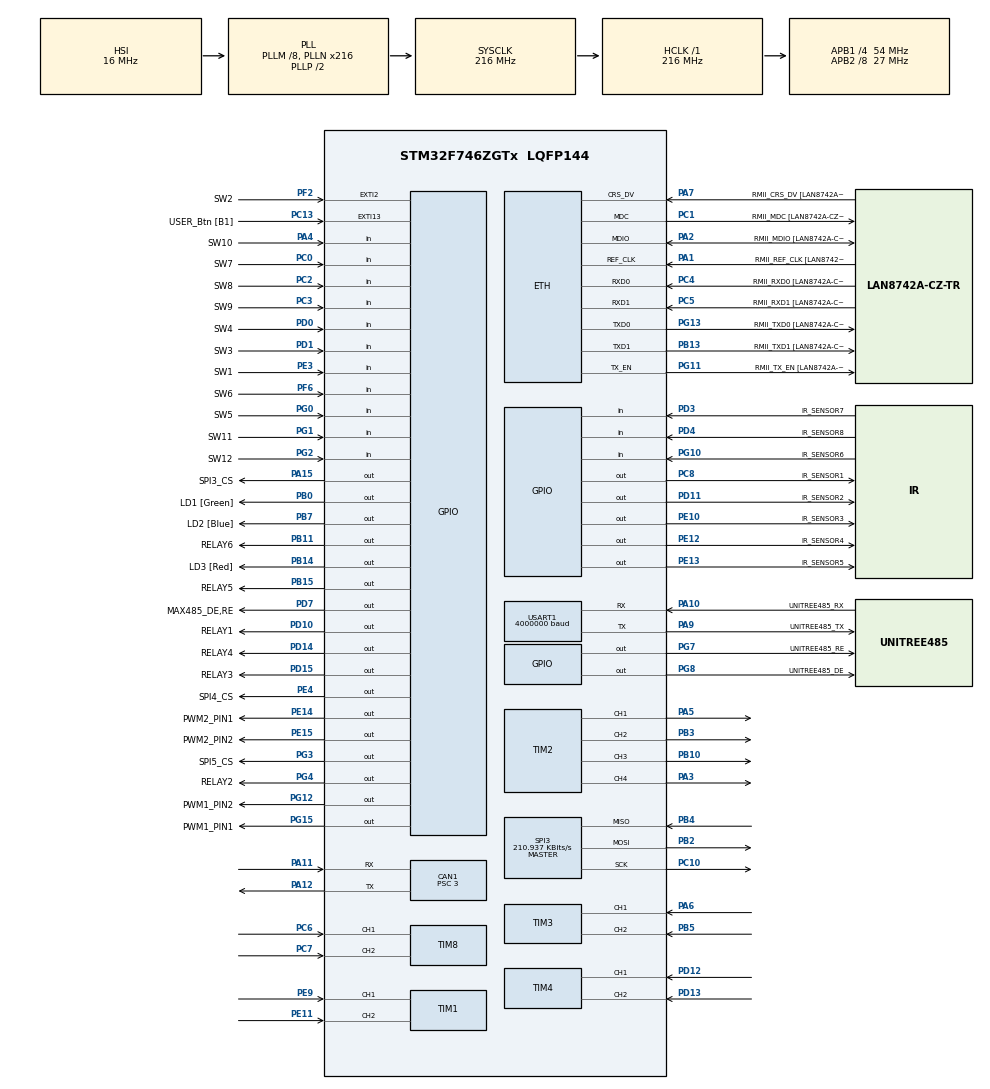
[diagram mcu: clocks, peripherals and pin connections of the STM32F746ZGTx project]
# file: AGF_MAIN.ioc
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CAN1.ABOM=ENABLE
CAN1.BS1=CAN_BS1_16TQ
CAN1.CalculateBaudRate=1000000
CAN1.CalculateTimeBit=1000
CAN1.CalculateTimeQuantum=55.55555555555556
CAN1.NART=ENABLE
CAN1.Prescaler=3
ETH.MediaInterface=HAL_ETH_RMII_MODE
ETH.PHY_Name=LAN8742A_PHY_ADDRESS
ETH.PHY_Value=0
ETH.PhyAddress=0
FREERTOS.Tasks01=Emergency,30,256,EmergencyTask,Default,NULL,Dynamic,NULL,NULL;JoyStick_Task,8,256,Joy_Task,Default,NULL,Dynamic,NULL,NULL;Motion_Control_,8,256,Motion_Control,Default,NULL,Dynamic,NULL,NULL
FREERTOS.configUSE_NEWLIB_REENTRANT=1
Mcu.Family=STM32F7
Mcu.Name=STM32F746ZGTx
Mcu.Package=LQFP144
NVIC.CAN1_RX0_IRQn=true\:5\:0\:false\:false\:true\:true\:true\:true\:true
NVIC.CAN1_RX1_IRQn=true\:5\:0\:false\:false\:true\:true\:true\:true\:true
NVIC.PriorityGroup=NVIC_PRIORITYGROUP_4
NVIC.TIM7_IRQn=true\:15\:0\:false\:false\:true\:false\:false\:true\:true
NVIC.TimeBase=TIM7_IRQn
NVIC.TimeBaseIP=TIM7
PA1.GPIO_Label=RMII_REF_CLK [LAN8742A-CZ-TR_REFCLK0]
PA1.Mode=RMII
PA1.Signal=ETH_REF_CLK
PA10.GPIO_Label=UNITREE485_RX
PA10.Mode=Asynchronous
PA10.Signal=USART1_RX
PA11.Mode=CAN_Activate
PA11.Signal=CAN1_RX
PA12.Mode=CAN_Activate
PA12.Signal=CAN1_TX
PA13.GPIO_Label=TMS
PA13.Mode=Serial_Wire
PA13.Signal=SYS_JTMS-SWDIO
PA14.GPIO_Label=TCK
PA14.Mode=Serial_Wire
PA14.Signal=SYS_JTCK-SWCLK
PA15.GPIO_Label=SPI3_CS
PA15.GPIO_Speed=GPIO_SPEED_FREQ_LOW
PA15.Signal=GPIO_Output
PA2.GPIO_Label=RMII_MDIO [LAN8742A-CZ-TR_MDIO]
PA2.Mode=RMII
PA2.Signal=ETH_MDIO
PA3.Signal=S_TIM2_CH4
PA4.GPIO_Label=SW10
PA4.Signal=GPIO_Input
PA5.Signal=S_TIM2_CH1_ETR
PA6.Signal=S_TIM3_CH1
PA7.GPIO_Label=RMII_CRS_DV [LAN8742A-CZ-TR_CRS_DV]
PA7.Mode=RMII
PA7.Signal=ETH_CRS_DV
PA9.GPIO_Label=UNITREE485_TX
PA9.Mode=Asynchronous
PA9.Signal=USART1_TX
PB0.GPIO_Label=LD1 [Green]
PB0.Signal=GPIO_Output
PB10.Signal=S_TIM2_CH3
PB11.GPIO_Label=RELAY6
PB11.Signal=GPIO_Output
PB13.GPIO_Label=RMII_TXD1 [LAN8742A-CZ-TR_TXD1]
PB13.Mode=RMII
PB13.Signal=ETH_TXD1
PB14.GPIO_Label=LD3 [Red]
PB14.Signal=GPIO_Output
PB15.GPIO_Label=RELAY5
PB15.Signal=GPIO_Output
PB2.Mode=Full_Duplex_Master
PB2.Signal=SPI3_MOSI
PB3.Signal=S_TIM2_CH2
PB4.Mode=Full_Duplex_Master
PB4.Signal=SPI3_MISO
PB5.Signal=S_TIM3_CH2
PB7.GPIO_Label=LD2 [Blue]
PB7.Signal=GPIO_Output
PB8.Signal=I2C1_SCL
PB9.Signal=I2C1_SDA
PC0.GPIO_Label=SW7
PC0.Signal=GPIO_Input
PC1.GPIO_Label=RMII_MDC [LAN8742A-CZ-TR_MDC]
PC1.Mode=RMII
PC1.Signal=ETH_MDC
PC10.Mode=Full_Duplex_Master
PC10.Signal=SPI3_SCK
PC13.GPIO_Label=USER_Btn [B1]
PC13.Signal=GPXTI13
PC14/OSC32_IN.Mode=LSE-External-Oscillator
PC14/OSC32_IN.Signal=RCC_OSC32_IN
PC15/OSC32_OUT.Mode=LSE-External-Oscillator
PC15/OSC32_OUT.Signal=RCC_OSC32_OUT
PC2.GPIO_Label=SW8
PC2.Signal=GPIO_Input
PC3.GPIO_Label=SW9
PC3.Signal=GPIO_Input
PC4.GPIO_Label=RMII_RXD0 [LAN8742A-CZ-TR_RXD0]
PC4.Mode=RMII
PC4.Signal=ETH_RXD0
PC5.GPIO_Label=RMII_RXD1 [LAN8742A-CZ-TR_RXD1]
PC5.Mode=RMII
PC5.Signal=ETH_RXD1
PC6.Signal=S_TIM8_CH1
PC7.Signal=S_TIM8_CH2
PC8.GPIO_Label=IR_SENSOR1
PC8.Signal=GPIO_Output
PD0.GPIO_Label=SW4
PD0.Signal=GPIO_Input
PD1.GPIO_Label=SW3
PD1.Signal=GPIO_Input
PD10.GPIO_Label=RELAY1
PD10.Signal=GPIO_Output
PD11.GPIO_Label=IR_SENSOR2
PD11.Signal=GPIO_Output
PD12.Signal=S_TIM4_CH1
PD13.Signal=S_TIM4_CH2
PD14.GPIO_Label=RELAY4
PD14.Signal=GPIO_Output
PD15.GPIO_Label=RELAY3
PD15.Signal=GPIO_Output
PD2.Signal=UART5_RX
PD3.GPIO_Label=IR_SENSOR7
PD3.Signal=GPIO_Input
PD4.GPIO_Label=IR_SENSOR8
PD4.Signal=GPIO_Input
PD6.GPIO_Label=MAX485_RO_RX
PD6.Signal=USART2_RX
PD7.GPIO_Label=MAX485_DE,RE
PD7.Signal=GPIO_Output
PD8.GPIO_Label=STLK_RX [STM32F103CBT6_PA3]
PD8.GPIO_PuPd=GPIO_PULLUP
PD8.Signal=USART3_TX
PD9.GPIO_Label=STLK_TX [STM32F103CBT6_PA2]
PD9.GPIO_PuPd=GPIO_PULLUP
PD9.Signal=USART3_RX
PE10.GPIO_Label=IR_SENSOR3
PE10.Signal=GPIO_Output
PE11.Signal=S_TIM1_CH2
PE12.GPIO_Label=IR_SENSOR4
PE12.Signal=GPIO_Output
PE13.GPIO_Label=IR_SENSOR5
PE13.Signal=GPIO_Output
PE14.GPIO_Label=PWM2_PIN1
PE14.Signal=GPIO_Output
PE15.GPIO_Label=PWM2_PIN2
PE15.Signal=GPIO_Output
PE3.GPIO_Label=SW1
PE3.Signal=GPIO_Input
PE4.GPIO_Label=SPI4_CS
PE4.Signal=GPIO_Output
PE7.Signal=UART7_RX
PE9.Signal=S_TIM1_CH1
PF2.GPIO_Label=SW2
PF2.GPIO_ModeDefaultEXTI=GPIO_MODE_IT_FALLING
PF2.Signal=GPXTI2
PF6.GPIO_Label=SW6
PF6.Signal=GPIO_Input
PG0.GPIO_Label=SW5
PG0.Signal=GPIO_Input
PG1.GPIO_Label=SW11
PG1.Signal=GPIO_Input
PG10.GPIO_Label=IR_SENSOR6
PG10.Signal=GPIO_Input
PG11.GPIO_Label=RMII_TX_EN [LAN8742A-CZ-TR_TXEN]
PG11.Mode=RMII
PG11.Signal=ETH_TX_EN
PG12.GPIO_Label=PWM1_PIN2
PG12.Signal=GPIO_Output
PG13.GPIO_Label=RMII_TXD0 [LAN8742A-CZ-TR_TXD0]
PG13.Mode=RMII
PG13.Signal=ETH_TXD0
PG15.GPIO_Label=PWM1_PIN1
PG15.Signal=GPIO_Output
PG2.GPIO_Label=SW12
PG2.Signal=GPIO_Input
PG3.GPIO_Label=SPI5_CS
PG3.Signal=GPIO_Output
PG4.GPIO_Label=RELAY2
PG4.Signal=GPIO_Output
PG7.GPIO_Label=UNITREE485_RE
PG7.Signal=GPIO_Output
PG8.GPIO_Label=UNITREE485_DE
PG8.Signal=GPIO_Output
PH0/OSC_IN.GPIO_Label=MCO [STM32F103CBT6_PA8]
PH0/OSC_IN.Mode=HSE-External-Oscillator
PH0/OSC_IN.Signal=RCC_OSC_IN
PH1/OSC_OUT.Mode=HSE-External-Oscillator
PH1/OSC_OUT.Signal=RCC_OSC_OUT
ProjectManager.HeapSize=0x200
ProjectManager.StackSize=0x400
ProjectManager.TargetToolchain=STM32CubeIDE
RCC.48MHZClocksFreq_Value=24000000
RCC.AHBFreq_Value=216000000
RCC.APB1CLKDivider=RCC_HCLK_DIV4
RCC.APB1Freq_Value=54000000
RCC.APB1TimFreq_Value=108000000
RCC.APB2CLKDivider=RCC_HCLK_DIV8
RCC.APB2Freq_Value=27000000
RCC.APB2TimFreq_Value=54000000
RCC.CortexFreq_Value=216000000
RCC.HCLKFreq_Value=216000000
RCC.HSE_VALUE=25000000
RCC.HSI_VALUE=16000000
RCC.PLLM=8
RCC.PLLMUL=RCC_PLL_MUL9
RCC.PLLN=216
RCC.PLLQ=3
RCC.PRESCALERUSB=RCC_USBCLKSOURCE_PLL_DIV1_5
RCC.SYSCLKFreq_VALUE=216000000
RCC.SYSCLKSource=RCC_SYSCLKSOURCE_PLLCLK
RCC.SYSCLKSourceVirtual=RCC_SYSCLKSOURCE_PLLCLK
RCC.USART1CLockSelection=RCC_USART1CLKSOURCE_SYSCLK
RCC.USBFreq_Value=144000000
RCC.VCOOutputFreq_Value=432000000
SH.S_TIM1_CH1.0=TIM1_CH1,Encoder_Interface
SH.S_TIM1_CH2.0=TIM1_CH2,Encoder_Interface
SH.S_TIM2_CH1_ETR.0=TIM2_CH1,PWM Generation1 CH1
SH.S_TIM2_CH2.0=TIM2_CH2,PWM Generation2 CH2
SH.S_TIM2_CH3.0=TIM2_CH3,PWM Generation3 CH3
SH.S_TIM2_CH4.0=TIM2_CH4,PWM Generation4 CH4
SH.S_TIM3_CH1.0=TIM3_CH1,Encoder_Interface
SH.S_TIM3_CH2.0=TIM3_CH2,Encoder_Interface
SH.S_TIM4_CH1.0=TIM4_CH1,Encoder_Interface
SH.S_TIM4_CH2.0=TIM4_CH2,Encoder_Interface
SH.S_TIM8_CH1.0=TIM8_CH1,Encoder_Interface
SH.S_TIM8_CH2.0=TIM8_CH2,Encoder_Interface
SPI3.BaudRatePrescaler=SPI_BAUDRATEPRESCALER_256
SPI3.CLKPhase=SPI_PHASE_1EDGE
SPI3.CLKPolarity=SPI_POLARITY_HIGH
SPI3.CalculateBaudRate=210.937 KBits/s
SPI3.DataSize=SPI_DATASIZE_8BIT
SPI3.Direction=SPI_DIRECTION_2LINES
SPI3.FirstBit=SPI_FIRSTBIT_LSB
SPI3.Mode=SPI_MODE_MASTER
SPI3.VirtualType=VM_MASTER
TIM2.Channel-PWM\ Generation1\ CH1=TIM_CHANNEL_1
TIM2.Channel-PWM\ Generation2\ CH2=TIM_CHANNEL_2
TIM2.Channel-PWM\ Generation3\ CH3=TIM_CHANNEL_3
TIM2.Channel-PWM\ Generation4\ CH4=TIM_CHANNEL_4
TIM3.EncoderMode=TIM_ENCODERMODE_TI12
TIM4.EncoderMode=TIM_ENCODERMODE_TI12
TIM8.CounterMode=TIM_COUNTERMODE_DOWN
TIM8.IC1Polarity=TIM_ICPOLARITY_RISING
USART1.BaudRate=4000000
USART1.VirtualMode-Asynchronous=VM_ASYNC
VP_FREERTOS_VS_CMSIS_V2.Mode=CMSIS_V2
VP_SYS_VS_tim7.Mode=TIM7
board=NUCLEO-F746ZG

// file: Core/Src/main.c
/* USER CODE BEGIN Header */
/**
  ******************************************************************************
  * @file           : main.c
  * @brief          : Main program body
  ******************************************************************************
  * @attention
  *
  * Copyright (c) 2026 STMicroelectronics.
  * All rights reserved.
  *
  * This software is licensed under terms that can be found in the LICENSE file
  * in the root directory of this software component.
  * If no LICENSE file comes with this software, it is provided AS-IS.
  *
  ******************************************************************************
  */
/* USER CODE END Header */
#include "main.h"
#include "string.h"
#include "cmsis_os.h"

/* USER CODE BEGIN Includes */
#include "WEncoder_CAN.h"
#include "motor_control.h"
#include "robstride.h"
/* USER CODE END Includes */

#if defined ( __ICCARM__ ) /*!< IAR Compiler */
#pragma location=0x2004c000
ETH_DMADescTypeDef  DMARxDscrTab[ETH_RX_DESC_CNT]; /* Ethernet Rx DMA Descriptors */
#pragma location=0x2004c0a0
ETH_DMADescTypeDef  DMATxDscrTab[ETH_TX_DESC_CNT]; /* Ethernet Tx DMA Descriptors */

#elif defined ( __CC_ARM )  /* MDK ARM Compiler */

__attribute__((at(0x2004c000))) ETH_DMADescTypeDef  DMARxDscrTab[ETH_RX_DESC_CNT]; /* Ethernet Rx DMA Descriptors */
__attribute__((at(0x2004c0a0))) ETH_DMADescTypeDef  DMATxDscrTab[ETH_TX_DESC_CNT]; /* Ethernet Tx DMA Descriptors */

#elif defined ( __GNUC__ ) /* GNU Compiler */

ETH_DMADescTypeDef DMARxDscrTab[ETH_RX_DESC_CNT] __attribute__((section(".RxDecripSection"))); /* Ethernet Rx DMA Descriptors */
ETH_DMADescTypeDef DMATxDscrTab[ETH_TX_DESC_CNT] __attribute__((section(".TxDecripSection")));   /* Ethernet Tx DMA Descriptors */
#endif

ETH_TxPacketConfig TxConfig;

CAN_HandleTypeDef hcan1;

ETH_HandleTypeDef heth;

SPI_HandleTypeDef hspi3;

TIM_HandleTypeDef htim1;
TIM_HandleTypeDef htim2;
TIM_HandleTypeDef htim3;
TIM_HandleTypeDef htim4;
TIM_HandleTypeDef htim8;

UART_HandleTypeDef huart1;

/* Definitions for Emergency */
osThreadId_t EmergencyHandle;
const osThreadAttr_t Emergency_attributes = {
  .name = "Emergency",
  .stack_size = 256 * 4,
  .priority = (osPriority_t) osPriorityNormal6,
};
/* Definitions for JoyStick_Task */
osThreadId_t JoyStick_TaskHandle;
const osThreadAttr_t JoyStick_Task_attributes = {
  .name = "JoyStick_Task",
  .stack_size = 256 * 4,
  .priority = (osPriority_t) osPriorityLow,
};
/* Definitions for Motion_Control_ */
osThreadId_t Motion_Control_Handle;
const osThreadAttr_t Motion_Control__attributes = {
  .name = "Motion_Control_",
  .stack_size = 256 * 4,
  .priority = (osPriority_t) osPriorityLow,
};

void SystemClock_Config(void);
static void MX_GPIO_Init(void);
static void MX_ETH_Init(void);
static void MX_CAN1_Init(void);
static void MX_SPI3_Init(void);
static void MX_TIM1_Init(void);
static void MX_TIM2_Init(void);
static void MX_TIM3_Init(void);
static void MX_TIM4_Init(void);
static void MX_TIM8_Init(void);
static void MX_USART1_UART_Init(void);
void EmergencyTask(void *argument);
void Joy_Task(void *argument);
void Motion_Control(void *argument);

int main(void)
{

  /* MCU Configuration--------------------------------------------------------*/

  /* Reset of all peripherals, Initializes the Flash interface and the Systick. */
  HAL_Init();

  /* Configure the system clock */
  SystemClock_Config();

  /* Initialize all configured peripherals */
  MX_GPIO_Init();
  MX_ETH_Init();
  MX_CAN1_Init();
  MX_SPI3_Init();
  MX_TIM1_Init();
  MX_TIM2_Init();
  MX_TIM3_Init();
  MX_TIM4_Init();
  MX_TIM8_Init();
  MX_USART1_UART_Init();

  /* Init scheduler */
  osKernelInitialize();

  /* Create the thread(s) */
  /* creation of Emergency */
  EmergencyHandle = osThreadNew(EmergencyTask, NULL, &Emergency_attributes);

  /* creation of JoyStick_Task */
  JoyStick_TaskHandle = osThreadNew(Joy_Task, NULL, &JoyStick_Task_attributes);

  /* creation of Motion_Control_ */
  Motion_Control_Handle = osThreadNew(Motion_Control, NULL, &Motion_Control__attributes);

  /* Start scheduler */
  osKernelStart();

  /* We should never get here as control is now taken by the scheduler */

  /* Infinite loop */
  while (1)
  {

  }
}

void SystemClock_Config(void)
{
  RCC_OscInitTypeDef RCC_OscInitStruct = {0};
  RCC_ClkInitTypeDef RCC_ClkInitStruct = {0};

  /** Configure LSE Drive Capability
  */
  HAL_PWR_EnableBkUpAccess();

  /** Configure the main internal regulator output voltage
  */
  __HAL_RCC_PWR_CLK_ENABLE();
  __HAL_PWR_VOLTAGESCALING_CONFIG(PWR_REGULATOR_VOLTAGE_SCALE1);

  /** Initializes the RCC Oscillators according to the specified parameters
  * in the RCC_OscInitTypeDef structure.
  */
  RCC_OscInitStruct.OscillatorType = RCC_OSCILLATORTYPE_HSI;
  RCC_OscInitStruct.HSIState = RCC_HSI_ON;
  RCC_OscInitStruct.HSICalibrationValue = RCC_HSICALIBRATION_DEFAULT;
  RCC_OscInitStruct.PLL.PLLState = RCC_PLL_ON;
  RCC_OscInitStruct.PLL.PLLSource = RCC_PLLSOURCE_HSI;
  RCC_OscInitStruct.PLL.PLLM = 8;
  RCC_OscInitStruct.PLL.PLLN = 216;
  RCC_OscInitStruct.PLL.PLLP = RCC_PLLP_DIV2;
  RCC_OscInitStruct.PLL.PLLQ = 3;
  if (HAL_RCC_OscConfig(&RCC_OscInitStruct) != HAL_OK)
  {
    Error_Handler();
  }

  /** Activate the Over-Drive mode
  */
  if (HAL_PWREx_EnableOverDrive() != HAL_OK)
  {
    Error_Handler();
  }

  /** Initializes the CPU, AHB and APB buses clocks
  */
  RCC_ClkInitStruct.ClockType = RCC_CLOCKTYPE_HCLK|RCC_CLOCKTYPE_SYSCLK
                              |RCC_CLOCKTYPE_PCLK1|RCC_CLOCKTYPE_PCLK2;
  RCC_ClkInitStruct.SYSCLKSource = RCC_SYSCLKSOURCE_PLLCLK;
  RCC_ClkInitStruct.AHBCLKDivider = RCC_SYSCLK_DIV1;
  RCC_ClkInitStruct.APB1CLKDivider = RCC_HCLK_DIV4;
  RCC_ClkInitStruct.APB2CLKDivider = RCC_HCLK_DIV8;

  if (HAL_RCC_ClockConfig(&RCC_ClkInitStruct, FLASH_LATENCY_7) != HAL_OK)
  {
    Error_Handler();
  }
}

static void MX_CAN1_Init(void)
{

  hcan1.Instance = CAN1;
  hcan1.Init.Prescaler = 3;
  hcan1.Init.Mode = CAN_MODE_NORMAL;
  hcan1.Init.SyncJumpWidth = CAN_SJW_1TQ;
  hcan1.Init.TimeSeg1 = CAN_BS1_16TQ;
  hcan1.Init.TimeSeg2 = CAN_BS2_1TQ;
  hcan1.Init.TimeTriggeredMode = DISABLE;
  hcan1.Init.AutoBusOff = ENABLE;
  hcan1.Init.AutoWakeUp = DISABLE;
  hcan1.Init.AutoRetransmission = ENABLE;
  hcan1.Init.ReceiveFifoLocked = DISABLE;
  hcan1.Init.TransmitFifoPriority = DISABLE;
  if (HAL_CAN_Init(&hcan1) != HAL_OK)
  {
    Error_Handler();
  }

}

static void MX_ETH_Init(void)
{

   static uint8_t MACAddr[6];

  heth.Instance = ETH;
  MACAddr[0] = 0x00;
  MACAddr[1] = 0x80;
  MACAddr[2] = 0xE1;
  MACAddr[3] = 0x00;
  MACAddr[4] = 0x00;
  MACAddr[5] = 0x00;
  heth.Init.MACAddr = &MACAddr[0];
  heth.Init.MediaInterface = HAL_ETH_RMII_MODE;
  heth.Init.TxDesc = DMATxDscrTab;
  heth.Init.RxDesc = DMARxDscrTab;
  heth.Init.RxBuffLen = 1524;

  if (HAL_ETH_Init(&heth) != HAL_OK)
  {
    Error_Handler();
  }

  memset(&TxConfig, 0 , sizeof(ETH_TxPacketConfig));
  TxConfig.Attributes = ETH_TX_PACKETS_FEATURES_CSUM | ETH_TX_PACKETS_FEATURES_CRCPAD;
  TxConfig.ChecksumCtrl = ETH_CHECKSUM_IPHDR_PAYLOAD_INSERT_PHDR_CALC;
  TxConfig.CRCPadCtrl = ETH_CRC_PAD_INSERT;

}

static void MX_SPI3_Init(void)
{

  /* SPI3 parameter configuration*/
  hspi3.Instance = SPI3;
  hspi3.Init.Mode = SPI_MODE_MASTER;
  hspi3.Init.Direction = SPI_DIRECTION_2LINES;
  hspi3.Init.DataSize = SPI_DATASIZE_8BIT;
  hspi3.Init.CLKPolarity = SPI_POLARITY_HIGH;
  hspi3.Init.CLKPhase = SPI_PHASE_1EDGE;
  hspi3.Init.NSS = SPI_NSS_SOFT;
  hspi3.Init.BaudRatePrescaler = SPI_BAUDRATEPRESCALER_256;
  hspi3.Init.FirstBit = SPI_FIRSTBIT_LSB;
  hspi3.Init.TIMode = SPI_TIMODE_DISABLE;
  hspi3.Init.CRCCalculation = SPI_CRCCALCULATION_DISABLE;
  hspi3.Init.CRCPolynomial = 7;
  hspi3.Init.CRCLength = SPI_CRC_LENGTH_DATASIZE;
  hspi3.Init.NSSPMode = SPI_NSS_PULSE_ENABLE;
  if (HAL_SPI_Init(&hspi3) != HAL_OK)
  {
    Error_Handler();
  }

}

static void MX_TIM1_Init(void)
{

  TIM_Encoder_InitTypeDef sConfig = {0};
  TIM_MasterConfigTypeDef sMasterConfig = {0};

  htim1.Instance = TIM1;
  htim1.Init.Prescaler = 0;
  htim1.Init.CounterMode = TIM_COUNTERMODE_UP;
  htim1.Init.Period = 65535;
  htim1.Init.ClockDivision = TIM_CLOCKDIVISION_DIV1;
  htim1.Init.RepetitionCounter = 0;
  htim1.Init.AutoReloadPreload = TIM_AUTORELOAD_PRELOAD_DISABLE;
  sConfig.EncoderMode = TIM_ENCODERMODE_TI1;
  sConfig.IC1Polarity = TIM_ICPOLARITY_RISING;
  sConfig.IC1Selection = TIM_ICSELECTION_DIRECTTI;
  sConfig.IC1Prescaler = TIM_ICPSC_DIV1;
  sConfig.IC1Filter = 0;
  sConfig.IC2Polarity = TIM_ICPOLARITY_RISING;
  sConfig.IC2Selection = TIM_ICSELECTION_DIRECTTI;
  sConfig.IC2Prescaler = TIM_ICPSC_DIV1;
  sConfig.IC2Filter = 0;
  if (HAL_TIM_Encoder_Init(&htim1, &sConfig) != HAL_OK)
  {
    Error_Handler();
  }
  sMasterConfig.MasterOutputTrigger = TIM_TRGO_RESET;
  sMasterConfig.MasterOutputTrigger2 = TIM_TRGO2_RESET;
  sMasterConfig.MasterSlaveMode = TIM_MASTERSLAVEMODE_DISABLE;
  if (HAL_TIMEx_MasterConfigSynchronization(&htim1, &sMasterConfig) != HAL_OK)
  {
    Error_Handler();
  }

}

static void MX_TIM2_Init(void)
{

  TIM_MasterConfigTypeDef sMasterConfig = {0};
  TIM_OC_InitTypeDef sConfigOC = {0};

  htim2.Instance = TIM2;
  htim2.Init.Prescaler = 0;
  htim2.Init.CounterMode = TIM_COUNTERMODE_UP;
  htim2.Init.Period = 4294967295;
  htim2.Init.ClockDivision = TIM_CLOCKDIVISION_DIV1;
  htim2.Init.AutoReloadPreload = TIM_AUTORELOAD_PRELOAD_DISABLE;
  if (HAL_TIM_PWM_Init(&htim2) != HAL_OK)
  {
    Error_Handler();
  }
  sMasterConfig.MasterOutputTrigger = TIM_TRGO_RESET;
  sMasterConfig.MasterSlaveMode = TIM_MASTERSLAVEMODE_DISABLE;
  if (HAL_TIMEx_MasterConfigSynchronization(&htim2, &sMasterConfig) != HAL_OK)
  {
    Error_Handler();
  }
  sConfigOC.OCMode = TIM_OCMODE_PWM1;
  sConfigOC.Pulse = 0;
  sConfigOC.OCPolarity = TIM_OCPOLARITY_HIGH;
  sConfigOC.OCFastMode = TIM_OCFAST_DISABLE;
  if (HAL_TIM_PWM_ConfigChannel(&htim2, &sConfigOC, TIM_CHANNEL_1) != HAL_OK)
  {
    Error_Handler();
  }
  if (HAL_TIM_PWM_ConfigChannel(&htim2, &sConfigOC, TIM_CHANNEL_2) != HAL_OK)
  {
    Error_Handler();
  }
  if (HAL_TIM_PWM_ConfigChannel(&htim2, &sConfigOC, TIM_CHANNEL_3) != HAL_OK)
  {
    Error_Handler();
  }
  if (HAL_TIM_PWM_ConfigChannel(&htim2, &sConfigOC, TIM_CHANNEL_4) != HAL_OK)
  {
    Error_Handler();
  }
  HAL_TIM_MspPostInit(&htim2);

}

static void MX_TIM3_Init(void)
{

  TIM_Encoder_InitTypeDef sConfig = {0};
  TIM_MasterConfigTypeDef sMasterConfig = {0};

  htim3.Instance = TIM3;
  htim3.Init.Prescaler = 0;
  htim3.Init.CounterMode = TIM_COUNTERMODE_UP;
  htim3.Init.Period = 65535;
  htim3.Init.ClockDivision = TIM_CLOCKDIVISION_DIV1;
  htim3.Init.AutoReloadPreload = TIM_AUTORELOAD_PRELOAD_DISABLE;
  sConfig.EncoderMode = TIM_ENCODERMODE_TI12;
  sConfig.IC1Polarity = TIM_ICPOLARITY_RISING;
  sConfig.IC1Selection = TIM_ICSELECTION_DIRECTTI;
  sConfig.IC1Prescaler = TIM_ICPSC_DIV1;
  sConfig.IC1Filter = 0;
  sConfig.IC2Polarity = TIM_ICPOLARITY_RISING;
  sConfig.IC2Selection = TIM_ICSELECTION_DIRECTTI;
  sConfig.IC2Prescaler = TIM_ICPSC_DIV1;
  sConfig.IC2Filter = 0;
  if (HAL_TIM_Encoder_Init(&htim3, &sConfig) != HAL_OK)
  {
    Error_Handler();
  }
  sMasterConfig.MasterOutputTrigger = TIM_TRGO_RESET;
  sMasterConfig.MasterSlaveMode = TIM_MASTERSLAVEMODE_DISABLE;
  if (HAL_TIMEx_MasterConfigSynchronization(&htim3, &sMasterConfig) != HAL_OK)
  {
    Error_Handler();
  }

}

static void MX_TIM4_Init(void)
{

  TIM_Encoder_InitTypeDef sConfig = {0};
  TIM_MasterConfigTypeDef sMasterConfig = {0};

  htim4.Instance = TIM4;
  htim4.Init.Prescaler = 0;
  htim4.Init.CounterMode = TIM_COUNTERMODE_UP;
  htim4.Init.Period = 65535;
  htim4.Init.ClockDivision = TIM_CLOCKDIVISION_DIV1;
  htim4.Init.AutoReloadPreload = TIM_AUTORELOAD_PRELOAD_DISABLE;
  sConfig.EncoderMode = TIM_ENCODERMODE_TI12;
  sConfig.IC1Polarity = TIM_ICPOLARITY_RISING;
  sConfig.IC1Selection = TIM_ICSELECTION_DIRECTTI;
  sConfig.IC1Prescaler = TIM_ICPSC_DIV1;
  sConfig.IC1Filter = 0;
  sConfig.IC2Polarity = TIM_ICPOLARITY_RISING;
  sConfig.IC2Selection = TIM_ICSELECTION_DIRECTTI;
  sConfig.IC2Prescaler = TIM_ICPSC_DIV1;
  sConfig.IC2Filter = 0;
  if (HAL_TIM_Encoder_Init(&htim4, &sConfig) != HAL_OK)
  {
    Error_Handler();
  }
  sMasterConfig.MasterOutputTrigger = TIM_TRGO_RESET;
  sMasterConfig.MasterSlaveMode = TIM_MASTERSLAVEMODE_DISABLE;
  if (HAL_TIMEx_MasterConfigSynchronization(&htim4, &sMasterConfig) != HAL_OK)
  {
    Error_Handler();
  }

}

static void MX_TIM8_Init(void)
{

  TIM_Encoder_InitTypeDef sConfig = {0};
  TIM_MasterConfigTypeDef sMasterConfig = {0};

  htim8.Instance = TIM8;
  htim8.Init.Prescaler = 0;
  htim8.Init.CounterMode = TIM_COUNTERMODE_DOWN;
  htim8.Init.Period = 65535;
  htim8.Init.ClockDivision = TIM_CLOCKDIVISION_DIV1;
  htim8.Init.RepetitionCounter = 0;
  htim8.Init.AutoReloadPreload = TIM_AUTORELOAD_PRELOAD_DISABLE;
  sConfig.EncoderMode = TIM_ENCODERMODE_TI1;
  sConfig.IC1Polarity = TIM_ICPOLARITY_RISING;
  sConfig.IC1Selection = TIM_ICSELECTION_DIRECTTI;
  sConfig.IC1Prescaler = TIM_ICPSC_DIV1;
  sConfig.IC1Filter = 0;
  sConfig.IC2Polarity = TIM_ICPOLARITY_RISING;
  sConfig.IC2Selection = TIM_ICSELECTION_DIRECTTI;
  sConfig.IC2Prescaler = TIM_ICPSC_DIV1;
  sConfig.IC2Filter = 0;
  if (HAL_TIM_Encoder_Init(&htim8, &sConfig) != HAL_OK)
  {
    Error_Handler();
  }
  sMasterConfig.MasterOutputTrigger = TIM_TRGO_RESET;
  sMasterConfig.MasterOutputTrigger2 = TIM_TRGO2_RESET;
  sMasterConfig.MasterSlaveMode = TIM_MASTERSLAVEMODE_DISABLE;
  if (HAL_TIMEx_MasterConfigSynchronization(&htim8, &sMasterConfig) != HAL_OK)
  {
    Error_Handler();
  }

}

static void MX_USART1_UART_Init(void)
{

  huart1.Instance = USART1;
  huart1.Init.BaudRate = 4000000;
  huart1.Init.WordLength = UART_WORDLENGTH_8B;
  huart1.Init.StopBits = UART_STOPBITS_1;
  huart1.Init.Parity = UART_PARITY_NONE;
  huart1.Init.Mode = UART_MODE_TX_RX;
  huart1.Init.HwFlowCtl = UART_HWCONTROL_NONE;
  huart1.Init.OverSampling = UART_OVERSAMPLING_16;
  huart1.Init.OneBitSampling = UART_ONE_BIT_SAMPLE_DISABLE;
  huart1.AdvancedInit.AdvFeatureInit = UART_ADVFEATURE_NO_INIT;
  if (HAL_UART_Init(&huart1) != HAL_OK)
  {
    Error_Handler();
  }

}

static void MX_GPIO_Init(void)
{
  GPIO_InitTypeDef GPIO_InitStruct = {0};

  /* GPIO Ports Clock Enable */
  __HAL_RCC_GPIOE_CLK_ENABLE();
  __HAL_RCC_GPIOC_CLK_ENABLE();
  __HAL_RCC_GPIOF_CLK_ENABLE();
  __HAL_RCC_GPIOH_CLK_ENABLE();
  __HAL_RCC_GPIOA_CLK_ENABLE();
  __HAL_RCC_GPIOB_CLK_ENABLE();
  __HAL_RCC_GPIOG_CLK_ENABLE();
  __HAL_RCC_GPIOD_CLK_ENABLE();

  /*Configure GPIO pin Output Level */
  HAL_GPIO_WritePin(GPIOE, SPI4_CS_Pin|IR_SENSOR3_Pin|IR_SENSOR4_Pin|IR_SENSOR5_Pin
                          |PWM2_PIN1_Pin|PWM2_PIN2_Pin, GPIO_PIN_RESET);

  /*Configure GPIO pin Output Level */
  HAL_GPIO_WritePin(GPIOB, LD1_Pin|RELAY6_Pin|LD3_Pin|RELAY5_Pin
                          |LD2_Pin, GPIO_PIN_RESET);

  /*Configure GPIO pin Output Level */
  HAL_GPIO_WritePin(GPIOD, RELAY1_Pin|IR_SENSOR2_Pin|RELAY4_Pin|RELAY3_Pin
                          |MAX485_DE_RE_Pin, GPIO_PIN_RESET);

  /*Configure GPIO pin Output Level */
  HAL_GPIO_WritePin(GPIOG, SPI5_CS_Pin|RELAY2_Pin|UNITREE485_RE_Pin|UNITREE485_DE_Pin
                          |PWM1_PIN2_Pin|PWM1_PIN1_Pin, GPIO_PIN_RESET);

  /*Configure GPIO pin Output Level */
  HAL_GPIO_WritePin(IR_SENSOR1_GPIO_Port, IR_SENSOR1_Pin, GPIO_PIN_RESET);

  /*Configure GPIO pin Output Level */
  HAL_GPIO_WritePin(SPI3_CS_GPIO_Port, SPI3_CS_Pin, GPIO_PIN_RESET);

  /*Configure GPIO pin : SW1_Pin */
  GPIO_InitStruct.Pin = SW1_Pin;
  GPIO_InitStruct.Mode = GPIO_MODE_INPUT;
  GPIO_InitStruct.Pull = GPIO_NOPULL;
  HAL_GPIO_Init(SW1_GPIO_Port, &GPIO_InitStruct);

  /*Configure GPIO pins : SPI4_CS_Pin IR_SENSOR3_Pin IR_SENSOR4_Pin IR_SENSOR5_Pin
                           PWM2_PIN1_Pin PWM2_PIN2_Pin */
  GPIO_InitStruct.Pin = SPI4_CS_Pin|IR_SENSOR3_Pin|IR_SENSOR4_Pin|IR_SENSOR5_Pin
                          |PWM2_PIN1_Pin|PWM2_PIN2_Pin;
  GPIO_InitStruct.Mode = GPIO_MODE_OUTPUT_PP;
  GPIO_InitStruct.Pull = GPIO_NOPULL;
  GPIO_InitStruct.Speed = GPIO_SPEED_FREQ_LOW;
  HAL_GPIO_Init(GPIOE, &GPIO_InitStruct);

  /*Configure GPIO pin : USER_Btn_Pin */
  GPIO_InitStruct.Pin = USER_Btn_Pin;
  GPIO_InitStruct.Mode = GPIO_MODE_IT_RISING;
  GPIO_InitStruct.Pull = GPIO_NOPULL;
  HAL_GPIO_Init(USER_Btn_GPIO_Port, &GPIO_InitStruct);

  /*Configure GPIO pin : SW2_Pin */
  GPIO_InitStruct.Pin = SW2_Pin;
  GPIO_InitStruct.Mode = GPIO_MODE_IT_FALLING;
  GPIO_InitStruct.Pull = GPIO_NOPULL;
  HAL_GPIO_Init(SW2_GPIO_Port, &GPIO_InitStruct);

  /*Configure GPIO pin : SW6_Pin */
  GPIO_InitStruct.Pin = SW6_Pin;
  GPIO_InitStruct.Mode = GPIO_MODE_INPUT;
  GPIO_InitStruct.Pull = GPIO_NOPULL;
  HAL_GPIO_Init(SW6_GPIO_Port, &GPIO_InitStruct);

  /*Configure GPIO pins : SW7_Pin SW8_Pin SW9_Pin */
  GPIO_InitStruct.Pin = SW7_Pin|SW8_Pin|SW9_Pin;
  GPIO_InitStruct.Mode = GPIO_MODE_INPUT;
  GPIO_InitStruct.Pull = GPIO_NOPULL;
  HAL_GPIO_Init(GPIOC, &GPIO_InitStruct);

  /*Configure GPIO pin : SW10_Pin */
  GPIO_InitStruct.Pin = SW10_Pin;
  GPIO_InitStruct.Mode = GPIO_MODE_INPUT;
  GPIO_InitStruct.Pull = GPIO_NOPULL;
  HAL_GPIO_Init(SW10_GPIO_Port, &GPIO_InitStruct);

  /*Configure GPIO pins : LD1_Pin RELAY6_Pin LD3_Pin RELAY5_Pin
                           LD2_Pin */
  GPIO_InitStruct.Pin = LD1_Pin|RELAY6_Pin|LD3_Pin|RELAY5_Pin
                          |LD2_Pin;
  GPIO_InitStruct.Mode = GPIO_MODE_OUTPUT_PP;
  GPIO_InitStruct.Pull = GPIO_NOPULL;
  GPIO_InitStruct.Speed = GPIO_SPEED_FREQ_LOW;
  HAL_GPIO_Init(GPIOB, &GPIO_InitStruct);

  /*Configure GPIO pins : SW5_Pin SW11_Pin SW12_Pin IR_SENSOR6_Pin */
  GPIO_InitStruct.Pin = SW5_Pin|SW11_Pin|SW12_Pin|IR_SENSOR6_Pin;
  GPIO_InitStruct.Mode = GPIO_MODE_INPUT;
  GPIO_InitStruct.Pull = GPIO_NOPULL;
  HAL_GPIO_Init(GPIOG, &GPIO_InitStruct);

  /*Configure GPIO pin : PE7 */
  GPIO_InitStruct.Pin = GPIO_PIN_7;
  GPIO_InitStruct.Mode = GPIO_MODE_AF_PP;
  GPIO_InitStruct.Pull = GPIO_NOPULL;
  GPIO_InitStruct.Speed = GPIO_SPEED_FREQ_VERY_HIGH;
  GPIO_InitStruct.Alternate = GPIO_AF8_UART7;
  HAL_GPIO_Init(GPIOE, &GPIO_InitStruct);

  /*Configure GPIO pins : STLK_RX_Pin STLK_TX_Pin */
  GPIO_InitStruct.Pin = STLK_RX_Pin|STLK_TX_Pin;
  GPIO_InitStruct.Mode = GPIO_MODE_AF_PP;
  GPIO_InitStruct.Pull = GPIO_PULLUP;
  GPIO_InitStruct.Speed = GPIO_SPEED_FREQ_VERY_HIGH;
  GPIO_InitStruct.Alternate = GPIO_AF7_USART3;
  HAL_GPIO_Init(GPIOD, &GPIO_InitStruct);

  /*Configure GPIO pins : RELAY1_Pin IR_SENSOR2_Pin RELAY4_Pin RELAY3_Pin
                           MAX485_DE_RE_Pin */
  GPIO_InitStruct.Pin = RELAY1_Pin|IR_SENSOR2_Pin|RELAY4_Pin|RELAY3_Pin
                          |MAX485_DE_RE_Pin;
  GPIO_InitStruct.Mode = GPIO_MODE_OUTPUT_PP;
  GPIO_InitStruct.Pull = GPIO_NOPULL;
  GPIO_InitStruct.Speed = GPIO_SPEED_FREQ_LOW;
  HAL_GPIO_Init(GPIOD, &GPIO_InitStruct);

  /*Configure GPIO pins : SPI5_CS_Pin RELAY2_Pin UNITREE485_RE_Pin UNITREE485_DE_Pin
                           PWM1_PIN2_Pin PWM1_PIN1_Pin */
  GPIO_InitStruct.Pin = SPI5_CS_Pin|RELAY2_Pin|UNITREE485_RE_Pin|UNITREE485_DE_Pin
                          |PWM1_PIN2_Pin|PWM1_PIN1_Pin;
  GPIO_InitStruct.Mode = GPIO_MODE_OUTPUT_PP;
  GPIO_InitStruct.Pull = GPIO_NOPULL;
  GPIO_InitStruct.Speed = GPIO_SPEED_FREQ_LOW;
  HAL_GPIO_Init(GPIOG, &GPIO_InitStruct);

  /*Configure GPIO pin : IR_SENSOR1_Pin */
  GPIO_InitStruct.Pin = IR_SENSOR1_Pin;
  GPIO_InitStruct.Mode = GPIO_MODE_OUTPUT_PP;
  GPIO_InitStruct.Pull = GPIO_NOPULL;
  GPIO_InitStruct.Speed = GPIO_SPEED_FREQ_LOW;
  HAL_GPIO_Init(IR_SENSOR1_GPIO_Port, &GPIO_InitStruct);

  /*Configure GPIO pin : SPI3_CS_Pin */
  GPIO_InitStruct.Pin = SPI3_CS_Pin;
  GPIO_InitStruct.Mode = GPIO_MODE_OUTPUT_PP;
  GPIO_InitStruct.Pull = GPIO_NOPULL;
  GPIO_InitStruct.Speed = GPIO_SPEED_FREQ_LOW;
  HAL_GPIO_Init(SPI3_CS_GPIO_Port, &GPIO_InitStruct);

  /*Configure GPIO pins : SW4_Pin SW3_Pin IR_SENSOR7_Pin IR_SENSOR8_Pin */
  GPIO_InitStruct.Pin = SW4_Pin|SW3_Pin|IR_SENSOR7_Pin|IR_SENSOR8_Pin;
  GPIO_InitStruct.Mode = GPIO_MODE_INPUT;
  GPIO_InitStruct.Pull = GPIO_NOPULL;
  HAL_GPIO_Init(GPIOD, &GPIO_InitStruct);

  /*Configure GPIO pin : PD2 */
  GPIO_InitStruct.Pin = GPIO_PIN_2;
  GPIO_InitStruct.Mode = GPIO_MODE_AF_PP;
  GPIO_InitStruct.Pull = GPIO_NOPULL;
  GPIO_InitStruct.Speed = GPIO_SPEED_FREQ_VERY_HIGH;
  GPIO_InitStruct.Alternate = GPIO_AF8_UART5;
  HAL_GPIO_Init(GPIOD, &GPIO_InitStruct);

  /*Configure GPIO pin : MAX485_RO_RX_Pin */
  GPIO_InitStruct.Pin = MAX485_RO_RX_Pin;
  GPIO_InitStruct.Mode = GPIO_MODE_AF_PP;
  GPIO_InitStruct.Pull = GPIO_NOPULL;
  GPIO_InitStruct.Speed = GPIO_SPEED_FREQ_VERY_HIGH;
  GPIO_InitStruct.Alternate = GPIO_AF7_USART2;
  HAL_GPIO_Init(MAX485_RO_RX_GPIO_Port, &GPIO_InitStruct);

  /*Configure GPIO pins : PB8 PB9 */
  GPIO_InitStruct.Pin = GPIO_PIN_8|GPIO_PIN_9;
  GPIO_InitStruct.Mode = GPIO_MODE_AF_OD;
  GPIO_InitStruct.Pull = GPIO_NOPULL;
  GPIO_InitStruct.Speed = GPIO_SPEED_FREQ_VERY_HIGH;
  GPIO_InitStruct.Alternate = GPIO_AF4_I2C1;
  HAL_GPIO_Init(GPIOB, &GPIO_InitStruct);

}

/* USER CODE BEGIN 4 */
void HAL_GPIO_EXTI_Callback(uint16_t pin) {
  if (pin == SW2_Pin) {

  }
}
/* USER CODE END 4 */

void EmergencyTask(void *argument)
{
  for(;;)
  {
    osDelay(1);
  }
}

void Joy_Task(void *argument)
{
  /* USER CODE BEGIN Joy_Task */
	 uint8_t TX[9] = {0x01,0x42,0,0,0,0,0,0,0};
  /* Infinite loop */
  for(;;)
  {
    osDelay(1);
  }
  /* USER CODE END Joy_Task */
}

void Motion_Control(void *argument)
{
  for(;;)
  {
    osDelay(1);
  }
}

void HAL_TIM_PeriodElapsedCallback(TIM_HandleTypeDef *htim)
{
  if (htim->Instance == TIM7)
  {
    HAL_IncTick();
  }
}

void Error_Handler(void)
{
  __disable_irq();
  while (1)
  {
  }
}
